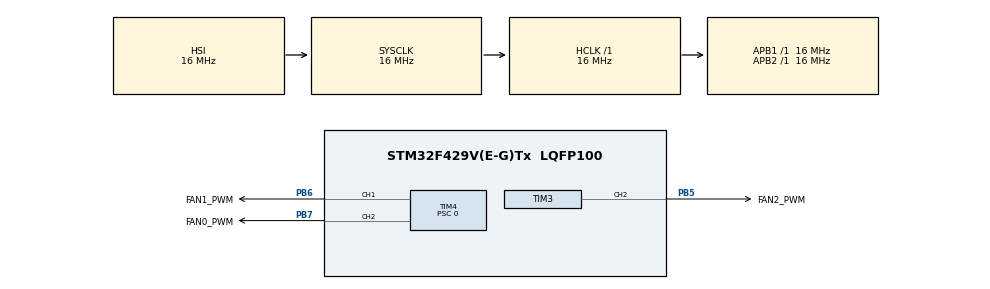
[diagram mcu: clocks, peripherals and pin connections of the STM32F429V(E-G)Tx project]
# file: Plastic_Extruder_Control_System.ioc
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FREERTOS.Tasks01=defaultTask,24,128,StartDefaultTask,Default,NULL,Dynamic,NULL,NULL
Mcu.Family=STM32F4
Mcu.Name=STM32F429V(E-G)Tx
Mcu.Package=LQFP100
NVIC.PriorityGroup=NVIC_PRIORITYGROUP_4
NVIC.TIM1_UP_TIM10_IRQn=true\:15\:0\:false\:false\:true\:false\:false\:true\:true
NVIC.TimeBase=TIM1_UP_TIM10_IRQn
NVIC.TimeBaseIP=TIM1
PB5.GPIO_Label=FAN2_PWM
PB5.GPIO_PuPd=GPIO_NOPULL
PB5.Signal=S_TIM3_CH2
PB6.GPIO_Label=FAN1_PWM
PB6.GPIO_PuPd=GPIO_NOPULL
PB6.Signal=S_TIM4_CH1
PB7.GPIO_Label=FAN0_PWM
PB7.GPIO_PuPd=GPIO_NOPULL
PB7.Signal=S_TIM4_CH2
ProjectManager.HeapSize=0x200
ProjectManager.StackSize=0x400
ProjectManager.TargetToolchain=CMake
RCC.AHBFreq_Value=16000000
RCC.APB1Freq_Value=16000000
RCC.APB2Freq_Value=16000000
RCC.CortexFreq_Value=16000000
RCC.HSE_VALUE=25000000
RCC.HSI_VALUE=16000000
RCC.LSE_VALUE=32768
RCC.SYSCLKFreq_VALUE=16000000
RCC.VCOOutputFreq_Value=192000000
SH.S_TIM3_CH2.0=TIM3_CH2,PWM Generation2 CH2
SH.S_TIM4_CH1.0=TIM4_CH1,PWM Generation1 CH1
SH.S_TIM4_CH2.0=TIM4_CH2,PWM Generation2 CH2
TIM3.Channel-PWM\ Generation2\ CH2=TIM_CHANNEL_2
TIM3.Prescaler=0
TIM4.Channel-PWM\ Generation1\ CH1=TIM_CHANNEL_1
TIM4.Channel-PWM\ Generation2\ CH2=TIM_CHANNEL_2
TIM4.Prescaler=0
TIM4.Pulse-PWM\ Generation1\ CH1=32768 
TIM4.Pulse-PWM\ Generation2\ CH2=32768 
VP_FREERTOS_VS_CMSIS_V2.Mode=CMSIS_V2
VP_SYS_VS_tim1.Mode=TIM1
VP_TIM3_VS_ClockSourceINT.Mode=Internal
VP_TIM4_VS_ClockSourceINT.Mode=Internal
board=custom

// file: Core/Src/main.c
/* USER CODE BEGIN Header */
/**
  ******************************************************************************
  * @file           : main.c
  * @brief          : Main program body
  ******************************************************************************
  * @attention
  *
  * Copyright (c) 2026 STMicroelectronics.
  * All rights reserved.
  *
  * This software is licensed under terms that can be found in the LICENSE file
  * in the root directory of this software component.
  * If no LICENSE file comes with this software, it is provided AS-IS.
  *
  ******************************************************************************
  */
/* USER CODE END Header */
#include "main.h"
#include "cmsis_os.h"

/* USER CODE BEGIN Includes */
//#include <Wire.h>            // I2C
//#include <NTC_Thermistor.h>  // Thermistor lib: https://github.com/suoapvs/NTC_Thermistor
//#include <TMCStepper.h>      // https://github.com/bigtreetech/TMCStepper
//#include "skr2_pins.h" // PIN assignments for BTT SKR2
#include "cmsis_os2.h"
#include "fans.c"
#include "projdefs.h"
/* USER CODE END Includes */

TIM_HandleTypeDef htim3;
TIM_HandleTypeDef htim4;

/* Definitions for defaultTask */
osThreadId_t defaultTaskHandle;
const osThreadAttr_t defaultTask_attributes = {
  .name = "defaultTask",
  .stack_size = 128 * 4,
  .priority = (osPriority_t) osPriorityNormal,
};
/* USER CODE BEGIN PV */
osThreadId_t FanControlTaskHandle;
const osThreadAttr_t fanControlTask_attributes = {
  .name = "fanControl",
  .stack_size = 256 * 4,
  .priority = (osPriority_t) osPriorityNormal,
};
/* USER CODE END PV */

void SystemClock_Config(void);
static void MX_GPIO_Init(void);
static void MX_TIM3_Init(void);
static void MX_TIM4_Init(void);
void StartDefaultTask(void *argument);

/* USER CODE BEGIN PFP */
void vFanControlTask(void *argument);
/* USER CODE END PFP */

int main(void)
{

  /* MCU Configuration--------------------------------------------------------*/

  /* Reset of all peripherals, Initializes the Flash interface and the Systick. */
  HAL_Init();

  /* Configure the system clock */
  SystemClock_Config();

  /* Initialize all configured peripherals */
  MX_GPIO_Init();
  MX_TIM3_Init();
  MX_TIM4_Init();

  /* Init scheduler */
  osKernelInitialize();

  /* Create the thread(s) */
  /* creation of defaultTask */
  defaultTaskHandle = osThreadNew(StartDefaultTask, NULL, &defaultTask_attributes);

  /* USER CODE BEGIN RTOS_THREADS */
  FanControlTaskHandle = osThreadNew(vFanControlTask, NULL, &fanControlTask_attributes);
  /* USER CODE END RTOS_THREADS */

  /* Start scheduler */
  osKernelStart();

  /* We should never get here as control is now taken by the scheduler */

  /* Infinite loop */
  while (1)
  {

  }
}

void SystemClock_Config(void)
{
  RCC_OscInitTypeDef RCC_OscInitStruct = {0};
  RCC_ClkInitTypeDef RCC_ClkInitStruct = {0};

  /** Configure the main internal regulator output voltage
  */
  __HAL_RCC_PWR_CLK_ENABLE();
  __HAL_PWR_VOLTAGESCALING_CONFIG(PWR_REGULATOR_VOLTAGE_SCALE3);

  /** Initializes the RCC Oscillators according to the specified parameters
  * in the RCC_OscInitTypeDef structure.
  */
  RCC_OscInitStruct.OscillatorType = RCC_OSCILLATORTYPE_HSI;
  RCC_OscInitStruct.HSIState = RCC_HSI_ON;
  RCC_OscInitStruct.HSICalibrationValue = RCC_HSICALIBRATION_DEFAULT;
  RCC_OscInitStruct.PLL.PLLState = RCC_PLL_NONE;
  if (HAL_RCC_OscConfig(&RCC_OscInitStruct) != HAL_OK)
  {
    Error_Handler();
  }

  /** Initializes the CPU, AHB and APB buses clocks
  */
  RCC_ClkInitStruct.ClockType = RCC_CLOCKTYPE_HCLK|RCC_CLOCKTYPE_SYSCLK
                              |RCC_CLOCKTYPE_PCLK1|RCC_CLOCKTYPE_PCLK2;
  RCC_ClkInitStruct.SYSCLKSource = RCC_SYSCLKSOURCE_HSI;
  RCC_ClkInitStruct.AHBCLKDivider = RCC_SYSCLK_DIV1;
  RCC_ClkInitStruct.APB1CLKDivider = RCC_HCLK_DIV1;
  RCC_ClkInitStruct.APB2CLKDivider = RCC_HCLK_DIV1;

  if (HAL_RCC_ClockConfig(&RCC_ClkInitStruct, FLASH_LATENCY_0) != HAL_OK)
  {
    Error_Handler();
  }
}

static void MX_TIM3_Init(void)
{

  TIM_ClockConfigTypeDef sClockSourceConfig = {0};
  TIM_MasterConfigTypeDef sMasterConfig = {0};
  TIM_OC_InitTypeDef sConfigOC = {0};

  htim3.Instance = TIM3;
  htim3.Init.Prescaler = 0;
  htim3.Init.CounterMode = TIM_COUNTERMODE_UP;
  htim3.Init.Period = 65535;
  htim3.Init.ClockDivision = TIM_CLOCKDIVISION_DIV1;
  htim3.Init.AutoReloadPreload = TIM_AUTORELOAD_PRELOAD_DISABLE;
  if (HAL_TIM_Base_Init(&htim3) != HAL_OK)
  {
    Error_Handler();
  }
  sClockSourceConfig.ClockSource = TIM_CLOCKSOURCE_INTERNAL;
  if (HAL_TIM_ConfigClockSource(&htim3, &sClockSourceConfig) != HAL_OK)
  {
    Error_Handler();
  }
  if (HAL_TIM_PWM_Init(&htim3) != HAL_OK)
  {
    Error_Handler();
  }
  sMasterConfig.MasterOutputTrigger = TIM_TRGO_RESET;
  sMasterConfig.MasterSlaveMode = TIM_MASTERSLAVEMODE_DISABLE;
  if (HAL_TIMEx_MasterConfigSynchronization(&htim3, &sMasterConfig) != HAL_OK)
  {
    Error_Handler();
  }
  sConfigOC.OCMode = TIM_OCMODE_PWM1;
  sConfigOC.Pulse = 0;
  sConfigOC.OCPolarity = TIM_OCPOLARITY_HIGH;
  sConfigOC.OCFastMode = TIM_OCFAST_DISABLE;
  if (HAL_TIM_PWM_ConfigChannel(&htim3, &sConfigOC, TIM_CHANNEL_2) != HAL_OK)
  {
    Error_Handler();
  }
  HAL_TIM_MspPostInit(&htim3);

}

static void MX_TIM4_Init(void)
{

  TIM_ClockConfigTypeDef sClockSourceConfig = {0};
  TIM_MasterConfigTypeDef sMasterConfig = {0};
  TIM_OC_InitTypeDef sConfigOC = {0};

  htim4.Instance = TIM4;
  htim4.Init.Prescaler = 0;
  htim4.Init.CounterMode = TIM_COUNTERMODE_UP;
  htim4.Init.Period = 65535;
  htim4.Init.ClockDivision = TIM_CLOCKDIVISION_DIV1;
  htim4.Init.AutoReloadPreload = TIM_AUTORELOAD_PRELOAD_DISABLE;
  if (HAL_TIM_Base_Init(&htim4) != HAL_OK)
  {
    Error_Handler();
  }
  sClockSourceConfig.ClockSource = TIM_CLOCKSOURCE_INTERNAL;
  if (HAL_TIM_ConfigClockSource(&htim4, &sClockSourceConfig) != HAL_OK)
  {
    Error_Handler();
  }
  if (HAL_TIM_PWM_Init(&htim4) != HAL_OK)
  {
    Error_Handler();
  }
  sMasterConfig.MasterOutputTrigger = TIM_TRGO_RESET;
  sMasterConfig.MasterSlaveMode = TIM_MASTERSLAVEMODE_DISABLE;
  if (HAL_TIMEx_MasterConfigSynchronization(&htim4, &sMasterConfig) != HAL_OK)
  {
    Error_Handler();
  }
  sConfigOC.OCMode = TIM_OCMODE_PWM1;
  sConfigOC.Pulse = 32768 ;
  sConfigOC.OCPolarity = TIM_OCPOLARITY_HIGH;
  sConfigOC.OCFastMode = TIM_OCFAST_DISABLE;
  if (HAL_TIM_PWM_ConfigChannel(&htim4, &sConfigOC, TIM_CHANNEL_1) != HAL_OK)
  {
    Error_Handler();
  }
  if (HAL_TIM_PWM_ConfigChannel(&htim4, &sConfigOC, TIM_CHANNEL_2) != HAL_OK)
  {
    Error_Handler();
  }
  HAL_TIM_MspPostInit(&htim4);

}

static void MX_GPIO_Init(void)
{

  /* GPIO Ports Clock Enable */
  __HAL_RCC_GPIOB_CLK_ENABLE();

}

/* USER CODE BEGIN 4 */
void vFanControlTask(void *argument)
{
  HAL_TIM_PWM_Start(&htim4, TIM_CHANNEL_1);
  HAL_TIM_PWM_Start(&htim4, TIM_CHANNEL_2);

  __HAL_TIM_SET_COMPARE(&htim4, TIM_CHANNEL_2, 0xDFFF);
  for(;;)
  {
    //Set_Fan_DutyCycle16(&htim4, TIM_CHANNEL_2, test_dc);
    osDelay(100);
  }
}
/* USER CODE END 4 */

void StartDefaultTask(void *argument)
{
  /* USER CODE BEGIN 5 */
  /* Infinite loop */
  for(;;)
  {
    osDelay(1000);
  }
  /* USER CODE END 5 */
}

void HAL_TIM_PeriodElapsedCallback(TIM_HandleTypeDef *htim)
{
  if (htim->Instance == TIM1)
  {
    HAL_IncTick();
  }
}

void Error_Handler(void)
{
  __disable_irq();
  while (1)
  {
  }
}
